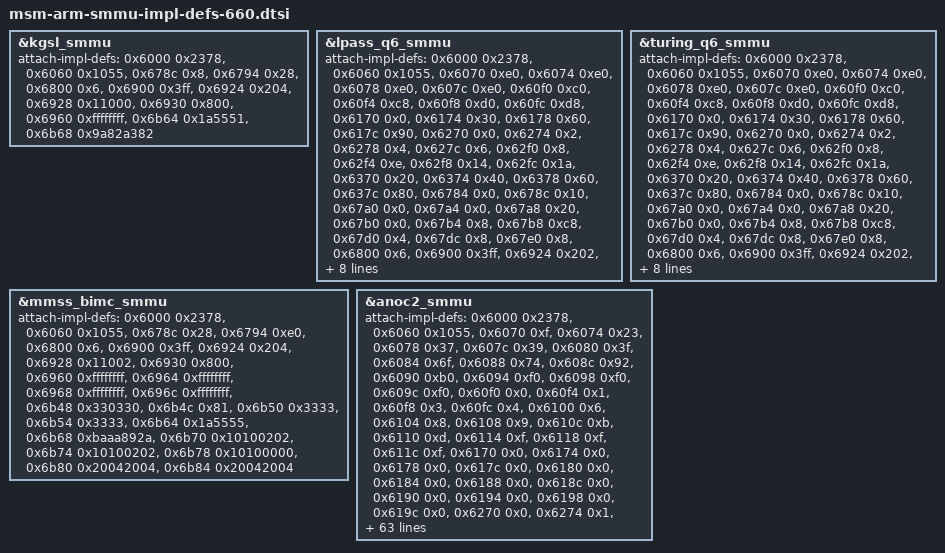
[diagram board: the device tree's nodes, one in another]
/* Copyright (c) 2016, The Linux Foundation. All rights reserved.
 *
 * This program is free software; you can redistribute it and/or modify
 * it under the terms of the GNU General Public License version 2 and
 * only version 2 as published by the Free Software Foundation.
 *
 * This program is distributed in the hope that it will be useful,
 * but WITHOUT ANY WARRANTY; without even the implied warranty of
 * MERCHANTABILITY or FITNESS FOR A PARTICULAR PURPOSE.  See the
 * GNU General Public License for more details.
 */

&kgsl_smmu {
	attach-impl-defs = <0x6000 0x2378>,
			   <0x6060 0x1055>,
			   <0x678c 0x8>,
			   <0x6794 0x28>,
			   <0x6800 0x6>,
			   <0x6900 0x3ff>,
			   <0x6924 0x204>,
			   <0x6928 0x11000>,
			   <0x6930 0x800>,
			   <0x6960 0xffffffff>,
			   <0x6b64 0x1a5551>,
			   <0x6b68 0x9a82a382>;
};

&lpass_q6_smmu {
	attach-impl-defs = <0x6000 0x2378>,
			   <0x6060 0x1055>,
			   <0x6070 0xe0>,
			   <0x6074 0xe0>,
			   <0x6078 0xe0>,
			   <0x607c 0xe0>,
			   <0x60f0 0xc0>,
			   <0x60f4 0xc8>,
			   <0x60f8 0xd0>,
			   <0x60fc 0xd8>,
			   <0x6170 0x0>,
			   <0x6174 0x30>,
			   <0x6178 0x60>,
			   <0x617c 0x90>,
			   <0x6270 0x0>,
			   <0x6274 0x2>,
			   <0x6278 0x4>,
			   <0x627c 0x6>,
			   <0x62f0 0x8>,
			   <0x62f4 0xe>,
			   <0x62f8 0x14>,
			   <0x62fc 0x1a>,
			   <0x6370 0x20>,
			   <0x6374 0x40>,
			   <0x6378 0x60>,
			   <0x637c 0x80>,
			   <0x6784 0x0>,
			   <0x678c 0x10>,
			   <0x67a0 0x0>,
			   <0x67a4 0x0>,
			   <0x67a8 0x20>,
			   <0x67b0 0x0>,
			   <0x67b4 0x8>,
			   <0x67b8 0xc8>,
			   <0x67d0 0x4>,
			   <0x67dc 0x8>,
			   <0x67e0 0x8>,
			   <0x6800 0x6>,
			   <0x6900 0x3ff>,
			   <0x6924 0x202>,
			   <0x6928 0x10a00>,
			   <0x6930 0x500>,
			   <0x6960 0xffffffff>,
			   <0x6b64 0x121151>,
			   <0x6b68 0xea800080>,
			   <0x6c00 0x0>,
			   <0x6c04 0x0>,
			   <0x6c08 0x0>,
			   <0x6c0c 0x0>,
			   <0x6c10 0x1>,
			   <0x6c14 0x1>,
			   <0x6c18 0x1>,
			   <0x6c1c 0x1>,
			   <0x6c20 0x2>,
			   <0x6c24 0x2>,
			   <0x6c28 0x2>,
			   <0x6c2c 0x2>,
			   <0x6c30 0x3>,
			   <0x6c34 0x3>,
			   <0x6c38 0x3>,
			   <0x6c3c 0x3>;
};

&turing_q6_smmu {
	attach-impl-defs = <0x6000 0x2378>,
			   <0x6060 0x1055>,
			   <0x6070 0xe0>,
			   <0x6074 0xe0>,
			   <0x6078 0xe0>,
			   <0x607c 0xe0>,
			   <0x60f0 0xc0>,
			   <0x60f4 0xc8>,
			   <0x60f8 0xd0>,
			   <0x60fc 0xd8>,
			   <0x6170 0x0>,
			   <0x6174 0x30>,
			   <0x6178 0x60>,
			   <0x617c 0x90>,
			   <0x6270 0x0>,
			   <0x6274 0x2>,
			   <0x6278 0x4>,
			   <0x627c 0x6>,
			   <0x62f0 0x8>,
			   <0x62f4 0xe>,
			   <0x62f8 0x14>,
			   <0x62fc 0x1a>,
			   <0x6370 0x20>,
			   <0x6374 0x40>,
			   <0x6378 0x60>,
			   <0x637c 0x80>,
			   <0x6784 0x0>,
			   <0x678c 0x10>,
			   <0x67a0 0x0>,
			   <0x67a4 0x0>,
			   <0x67a8 0x20>,
			   <0x67b0 0x0>,
			   <0x67b4 0x8>,
			   <0x67b8 0xc8>,
			   <0x67d0 0x4>,
			   <0x67dc 0x8>,
			   <0x67e0 0x8>,
			   <0x6800 0x6>,
			   <0x6900 0x3ff>,
			   <0x6924 0x202>,
			   <0x6928 0x10a00>,
			   <0x6930 0x500>,
			   <0x6960 0xffffffff>,
			   <0x6b64 0x121151>,
			   <0x6b68 0xea800080>,
			   <0x6c00 0x0>,
			   <0x6c04 0x0>,
			   <0x6c08 0x0>,
			   <0x6c0c 0x0>,
			   <0x6c10 0x1>,
			   <0x6c14 0x1>,
			   <0x6c18 0x1>,
			   <0x6c1c 0x1>,
			   <0x6c20 0x2>,
			   <0x6c24 0x2>,
			   <0x6c28 0x2>,
			   <0x6c2c 0x2>,
			   <0x6c30 0x3>,
			   <0x6c34 0x3>,
			   <0x6c38 0x3>,
			   <0x6c3c 0x3>;
};

&mmss_bimc_smmu {
	attach-impl-defs = <0x6000 0x2378>,
			   <0x6060 0x1055>,
			   <0x678c 0x28>,
			   <0x6794 0xe0>,
			   <0x6800 0x6>,
			   <0x6900 0x3ff>,
			   <0x6924 0x204>,
			   <0x6928 0x11002>,
			   <0x6930 0x800>,
			   <0x6960 0xffffffff>,
			   <0x6964 0xffffffff>,
			   <0x6968 0xffffffff>,
			   <0x696c 0xffffffff>,
			   <0x6b48 0x330330>,
			   <0x6b4c 0x81>,
			   <0x6b50 0x3333>,
			   <0x6b54 0x3333>,
			   <0x6b64 0x1a5555>,
			   <0x6b68 0xbaaa892a>,
			   <0x6b70 0x10100202>,
			   <0x6b74 0x10100202>,
			   <0x6b78 0x10100000>,
			   <0x6b80 0x20042004>,
			   <0x6b84 0x20042004>;
};

&anoc2_smmu {
	attach-impl-defs = <0x6000 0x2378>,
			   <0x6060 0x1055>,
			   <0x6070 0xf>,
			   <0x6074 0x23>,
			   <0x6078 0x37>,
			   <0x607c 0x39>,
			   <0x6080 0x3f>,
			   <0x6084 0x6f>,
			   <0x6088 0x74>,
			   <0x608c 0x92>,
			   <0x6090 0xb0>,
			   <0x6094 0xf0>,
			   <0x6098 0xf0>,
			   <0x609c 0xf0>,
			   <0x60f0 0x0>,
			   <0x60f4 0x1>,
			   <0x60f8 0x3>,
			   <0x60fc 0x4>,
			   <0x6100 0x6>,
			   <0x6104 0x8>,
			   <0x6108 0x9>,
			   <0x610c 0xb>,
			   <0x6110 0xd>,
			   <0x6114 0xf>,
			   <0x6118 0xf>,
			   <0x611c 0xf>,
			   <0x6170 0x0>,
			   <0x6174 0x0>,
			   <0x6178 0x0>,
			   <0x617c 0x0>,
			   <0x6180 0x0>,
			   <0x6184 0x0>,
			   <0x6188 0x0>,
			   <0x618c 0x0>,
			   <0x6190 0x0>,
			   <0x6194 0x0>,
			   <0x6198 0x0>,
			   <0x619c 0x0>,
			   <0x6270 0x0>,
			   <0x6274 0x1>,
			   <0x6278 0x2>,
			   <0x627c 0x4>,
			   <0x6280 0x4>,
			   <0x6284 0x6>,
			   <0x6288 0x6>,
			   <0x628c 0xa>,
			   <0x6290 0xc>,
			   <0x6294 0xc>,
			   <0x6298 0xc>,
			   <0x629c 0xc>,
			   <0x62f0 0xc>,
			   <0x62f4 0x12>,
			   <0x62f8 0x18>,
			   <0x62fc 0x1a>,
			   <0x6300 0x1d>,
			   <0x6304 0x23>,
			   <0x6308 0x24>,
			   <0x630c 0x28>,
			   <0x6310 0x2c>,
			   <0x6314 0x30>,
			   <0x6318 0x30>,
			   <0x631c 0x30>,
			   <0x6370 0x30>,
			   <0x6374 0x35>,
			   <0x6378 0x3a>,
			   <0x637c 0x3e>,
			   <0x6380 0x46>,
			   <0x6384 0x50>,
			   <0x6388 0x55>,
			   <0x638c 0x5d>,
			   <0x6390 0x67>,
			   <0x6394 0x80>,
			   <0x6398 0x80>,
			   <0x639c 0x80>,
			   <0x678c 0x12>,
			   <0x6794 0x32>,
			   <0x67a0 0x0>,
			   <0x67a4 0xe1>,
			   <0x67a8 0xf0>,
			   <0x67b0 0x0>,
			   <0x67b4 0xc>,
			   <0x67b8 0x9c>,
			   <0x67d0 0x0>,
			   <0x67dc 0x4>,
			   <0x67e0 0x8>,
			   <0x6800 0x6>,
			   <0x6900 0x3ff>,
			   <0x6b48 0x330330>,
			   <0x6b4c 0x81>,
			   <0x6b50 0x1313>,
			   <0x6b64 0x121155>,
			   <0x6b68 0xcaa84920>,
			   <0x6b70 0xc0c0000>,
			   <0x6b74 0x8080000>,
			   <0x6b78 0x8080000>,
			   <0x6b80 0x20002000>,
			   <0x6b84 0x20002000>,
			   <0x6c00 0x5>,
			   <0x6c04 0x0>,
			   <0x6c08 0x5>,
			   <0x6c0c 0x0>,
			   <0x6c10 0x5>,
			   <0x6c14 0x0>,
			   <0x6c18 0x5>,
			   <0x6c1c 0x0>,
			   <0x6c20 0x5>,
			   <0x6c24 0x0>,
			   <0x6c28 0x0>,
			   <0x6c2c 0x0>,
			   <0x6c30 0x0>,
			   <0x6c34 0x0>,
			   <0x6c38 0x0>,
			   <0x6c3c 0x0>,
			   <0x6c40 0x0>,
			   <0x6c44 0x0>,
			   <0x6c48 0x0>,
			   <0x6c4c 0x0>,
			   <0x6c50 0x0>,
			   <0x6c54 0x0>,
			   <0x6c58 0x0>,
			   <0x6c5c 0x0>,
			   <0x6c60 0x0>,
			   <0x6c64 0x0>,
			   <0x6c68 0x0>,
			   <0x6c6c 0x0>,
			   <0x6c70 0x0>,
			   <0x6c74 0x0>,
			   <0x6c78 0x0>,
			   <0x6c7c 0x0>,
			   <0x6c80 0x0>,
			   <0x6c84 0x0>,
			   <0x6c88 0x0>,
			   <0x6c8c 0x0>,
			   <0x6c90 0x0>,
			   <0x6c94 0x0>,
			   <0x6c98 0x0>,
			   <0x6c9c 0x0>,
			   <0x6ca0 0x0>,
			   <0x6ca4 0x0>,
			   <0x6ca8 0x0>,
			   <0x6cac 0x0>,
			   <0x6cb0 0x0>,
			   <0x6cb4 0x0>,
			   <0x6cb8 0x0>,
			   <0x6cbc 0x0>,
			   <0x6cc0 0x0>,
			   <0x6cc4 0x0>,
			   <0x6cc8 0x0>,
			   <0x6ccc 0x0>,
			   <0x6cd0 0x0>,
			   <0x6cd4 0x0>,
			   <0x6cd8 0x0>,
			   <0x6cdc 0x0>,
			   <0x6ce0 0x0>,
			   <0x6ce4 0x0>,
			   <0x6ce8 0x0>,
			   <0x6cec 0x0>,
			   <0x6cf0 0x0>,
			   <0x6cf4 0x0>,
			   <0x6cf8 0x0>,
			   <0x6cfc 0x0>,
			   <0x6d00 0x3>,
			   <0x6d04 0x4>,
			   <0x6d08 0x4>,
			   <0x6d0c 0x0>,
			   <0x6d10 0x8>,
			   <0x6d14 0x8>,
			   <0x6d18 0x3>,
			   <0x6d1c 0x2>,
			   <0x6d20 0x4>,
			   <0x6d24 0x0>,
			   <0x6d28 0x4>,
			   <0x6d2c 0x0>,
			   <0x6d30 0x7>,
			   <0x6d34 0x0>,
			   <0x6d38 0x6>,
			   <0x6d3c 0x0>,
			   <0x6d40 0x0>,
			   <0x6d44 0x1>,
			   <0x6d48 0x4>,
			   <0x6d4c 0x0>,
			   <0x6d50 0x4>,
			   <0x6d54 0x0>,
			   <0x6d58 0x4>,
			   <0x6d5c 0x0>,
			   <0x6d60 0x0>,
			   <0x6d64 0x0>,
			   <0x6d68 0x0>,
			   <0x6d6c 0x0>,
			   <0x6d70 0x0>,
			   <0x6d74 0x0>,
			   <0x6d78 0x0>,
			   <0x6d7c 0x0>,
			   <0x6d80 0x0>,
			   <0x6d84 0x0>,
			   <0x6d88 0x0>,
			   <0x6d8c 0x0>,
			   <0x6d90 0x0>,
			   <0x6d94 0x0>,
			   <0x6d98 0x0>,
			   <0x6d9c 0x0>,
			   <0x6da0 0x0>,
			   <0x6da4 0x0>,
			   <0x6da8 0x0>,
			   <0x6dac 0x0>,
			   <0x6db0 0x0>,
			   <0x6db4 0x0>,
			   <0x6db8 0x0>,
			   <0x6dbc 0x0>,
			   <0x6dc0 0x0>,
			   <0x6dc4 0x0>,
			   <0x6dc8 0x0>,
			   <0x6dcc 0x0>,
			   <0x6dd0 0x0>,
			   <0x6dd4 0x0>,
			   <0x6dd8 0x0>,
			   <0x6ddc 0x0>,
			   <0x6de0 0x0>,
			   <0x6de4 0x0>,
			   <0x6de8 0x0>,
			   <0x6dec 0x0>,
			   <0x6df0 0x0>,
			   <0x6df4 0x0>,
			   <0x6df8 0x0>,
			   <0x6dfc 0x0>;
};
